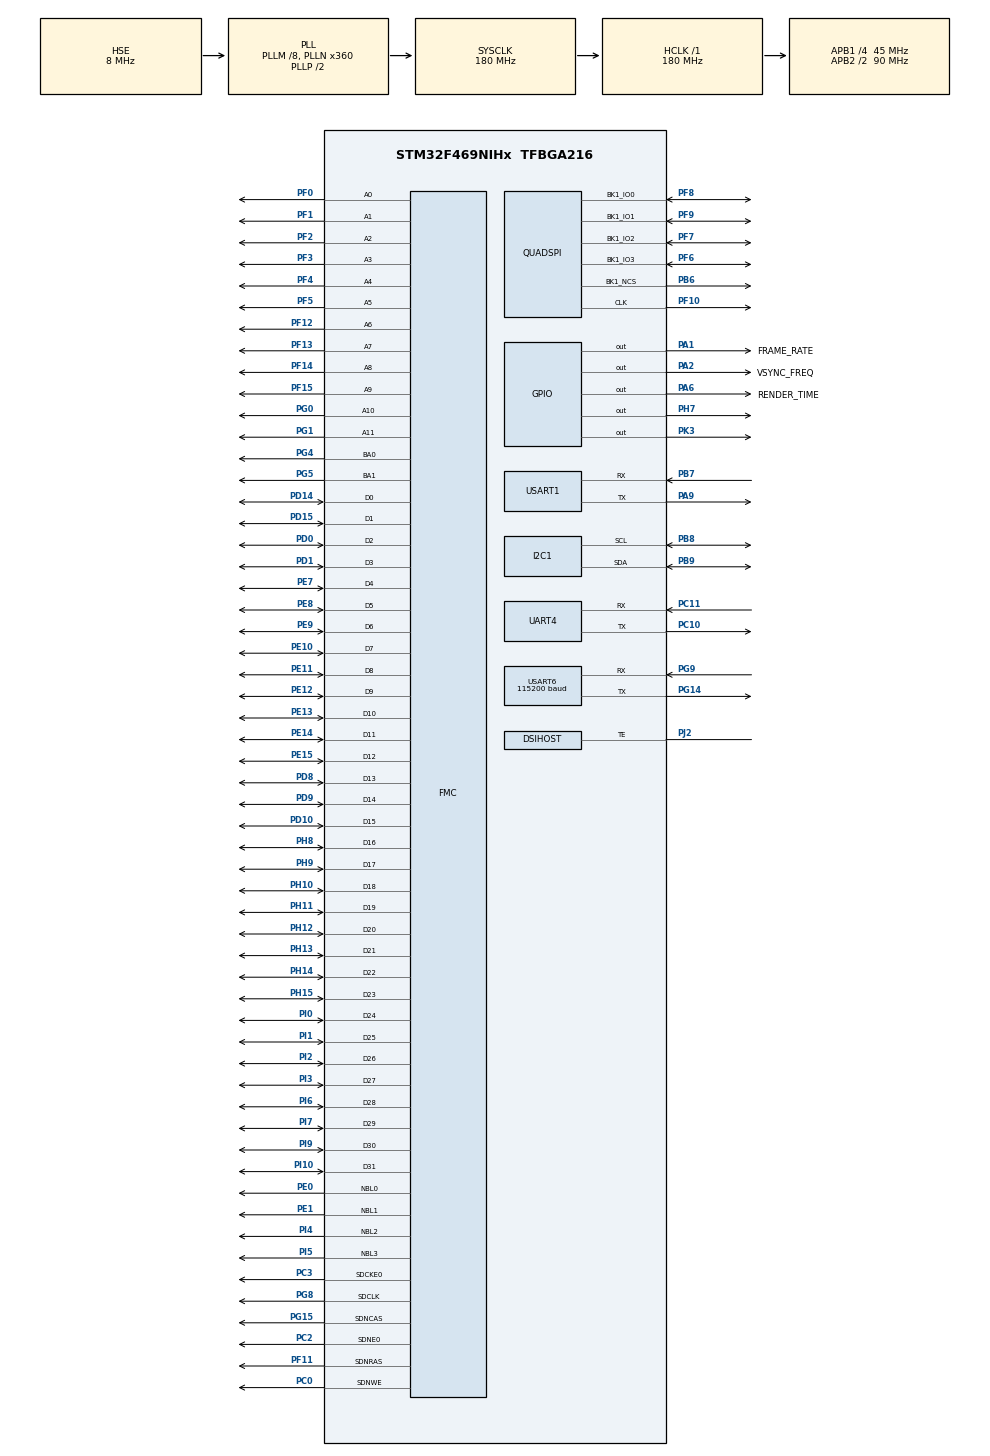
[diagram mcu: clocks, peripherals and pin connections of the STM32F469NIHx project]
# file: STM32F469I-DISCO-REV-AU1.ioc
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DMA2D.ColorMode=DMA2D_OUTPUT_ARGB8888
DSIHOST.AcknowledgeRequest=DSI_ACKNOWLEDGE_ENABLE
DSIHOST.AutomaticRefresh=DSI_AR_DISABLE
DSIHOST.CommandSize=200
DSIHOST.LPDcsLongWrite=DSI_LP_DLW_ENABLE
DSIHOST.LPDcsShortReadNoP=DSI_LP_DSR0P_ENABLE
DSIHOST.LPDcsShortWriteNoP=DSI_LP_DSW0P_ENABLE
DSIHOST.LPDcsShortWriteOneP=DSI_LP_DSW1P_ENABLE
DSIHOST.LPGenLongWrite=DSI_LP_GLW_ENABLE
DSIHOST.LPGenShortReadNoP=DSI_LP_GSR0P_ENABLE
DSIHOST.LPGenShortReadOneP=DSI_LP_GSR1P_ENABLE
DSIHOST.LPGenShortReadTwoP=DSI_LP_GSR2P_ENABLE
DSIHOST.LPGenShortWriteNoP=DSI_LP_GSW0P_ENABLE
DSIHOST.LPGenShortWriteOneP=DSI_LP_GSW1P_ENABLE
DSIHOST.LPGenShortWriteTwoP=DSI_LP_GSW2P_ENABLE
DSIHOST.LPMaxReadPacket=DSI_LP_MRDP_ENABLE
DSIHOST.NumberOfLanes=DSI_TWO_DATA_LANES
DSIHOST.TEAcknowledgeRequest=DSI_TE_ACKNOWLEDGE_ENABLE
DSIHOST.TimeoutCkdiv=1
DSIHOST_CKN.Mode=DSIHost_Adapted_TE
DSIHOST_CKN.Signal=DSIHOST_CKN
DSIHOST_CKP.Mode=DSIHost_Adapted_TE
DSIHOST_CKP.Signal=DSIHOST_CKP
DSIHOST_D0N.Mode=DSIHost_Adapted_TE
DSIHOST_D0N.Signal=DSIHOST_D0N
DSIHOST_D0P.Mode=DSIHost_Adapted_TE
DSIHOST_D0P.Signal=DSIHOST_D0P
DSIHOST_D1N.Mode=DSIHost_Adapted_TE
DSIHOST_D1N.Signal=DSIHOST_D1N
DSIHOST_D1P.Mode=DSIHost_Adapted_TE
DSIHOST_D1P.Signal=DSIHOST_D1P
Dma.Request0=UART4_RX
Dma.Request1=UART4_TX
Dma.UART4_RX.0.Direction=DMA_PERIPH_TO_MEMORY
Dma.UART4_RX.0.FIFOMode=DMA_FIFOMODE_DISABLE
Dma.UART4_RX.0.Instance=DMA1_Stream2
Dma.UART4_RX.0.MemDataAlignment=DMA_MDATAALIGN_BYTE
Dma.UART4_RX.0.MemInc=DMA_MINC_ENABLE
Dma.UART4_RX.0.Mode=DMA_NORMAL
Dma.UART4_RX.0.PeriphDataAlignment=DMA_PDATAALIGN_BYTE
Dma.UART4_RX.0.PeriphInc=DMA_PINC_DISABLE
Dma.UART4_RX.0.Priority=DMA_PRIORITY_LOW
Dma.UART4_TX.1.Direction=DMA_MEMORY_TO_PERIPH
Dma.UART4_TX.1.FIFOMode=DMA_FIFOMODE_DISABLE
Dma.UART4_TX.1.Instance=DMA1_Stream4
Dma.UART4_TX.1.MemDataAlignment=DMA_MDATAALIGN_BYTE
Dma.UART4_TX.1.MemInc=DMA_MINC_ENABLE
Dma.UART4_TX.1.Mode=DMA_NORMAL
Dma.UART4_TX.1.PeriphDataAlignment=DMA_PDATAALIGN_BYTE
Dma.UART4_TX.1.PeriphInc=DMA_PINC_DISABLE
Dma.UART4_TX.1.Priority=DMA_PRIORITY_LOW
FMC.CASLatency1=FMC_SDRAM_CAS_LATENCY_3
FMC.ExitSelfRefreshDelay1=7
FMC.LoadToActiveDelay1=2
FMC.RCDDelay1=2
FMC.RPDelay1=2
FMC.ReadBurst1=FMC_SDRAM_RBURST_ENABLE
FMC.ReadPipeDelay1=FMC_SDRAM_RPIPE_DELAY_2
FMC.RowCycleDelay1=7
FMC.SelfRefreshTime1=4
FMC.WriteRecoveryTime1=3
FREERTOS.Queues01=uartQueue,2,uint16_t,0,Dynamic,NULL,NULL
FREERTOS.Tasks01=defaultTask,24,128,StartDefaultTask,Default,NULL,Dynamic,NULL,NULL;TouchGFXTask,24,4096,TouchGFX_Task,As external,NULL,Dynamic,NULL,NULL
FREERTOS.configTOTAL_HEAP_SIZE=32768
FREERTOS.configUSE_APPLICATION_TASK_TAG=1
FREERTOS.configUSE_IDLE_HOOK=1
FREERTOS.configUSE_TRACE_FACILITY=1
I2C1.I2C_Mode=I2C_Fast
LTDC.ActiveW=200
LTDC.Alpha_L0=255
LTDC.FBStartAdress_L0=0xC0000000
LTDC.HBP=1
LTDC.HFP=1
LTDC.HSPolarity=LTDC_HSPOLARITY_AH
LTDC.HSync=2
LTDC.ImageHeight_L0=480
LTDC.ImageWidth_L0=200
LTDC.Layers=0
LTDC.PixelFormat_L0=LTDC_PIXEL_FORMAT_RGB565
LTDC.VBP=1
LTDC.VFP=1
LTDC.VSPolarity=LTDC_VSPOLARITY_AH
LTDC.VSync=2
LTDC.WindowX1_L0=200
LTDC.WindowY1_L0=480
Mcu.Family=STM32F4
Mcu.Name=STM32F469NIHx
Mcu.Package=TFBGA216
NVIC.DMA1_Stream2_IRQn=true\:5\:0\:false\:false\:true\:true\:false\:true\:true
NVIC.DMA1_Stream4_IRQn=true\:5\:0\:false\:false\:true\:true\:false\:true\:true
NVIC.DMA2D_IRQn=true\:5\:0\:true\:false\:true\:false\:true\:true\:true
NVIC.DSI_IRQn=true\:5\:0\:true\:false\:true\:false\:true\:true\:true
NVIC.LTDC_IRQn=true\:5\:0\:true\:false\:true\:false\:true\:true\:true
NVIC.PriorityGroup=NVIC_PRIORITYGROUP_4
NVIC.TIM6_DAC_IRQn=true\:0\:0\:false\:false\:true\:false\:false\:true\:true
NVIC.TimeBase=TIM6_DAC_IRQn
NVIC.TimeBaseIP=TIM6
NVIC.UART4_IRQn=true\:5\:0\:false\:false\:true\:true\:true\:true\:true
NVIC.USART1_IRQn=true\:5\:0\:false\:false\:true\:true\:true\:true\:true
NVIC.USART6_IRQn=true\:5\:0\:false\:false\:true\:true\:true\:true\:true
PA1.GPIO_Label=FRAME_RATE
PA1.GPIO_Speed=GPIO_SPEED_FREQ_VERY_HIGH
PA1.Signal=GPIO_Output
PA2.GPIO_Label=VSYNC_FREQ
PA2.GPIO_Speed=GPIO_SPEED_FREQ_VERY_HIGH
PA2.Signal=GPIO_Output
PA6.GPIO_Label=RENDER_TIME
PA6.GPIO_Speed=GPIO_SPEED_FREQ_VERY_HIGH
PA6.Signal=GPIO_Output
PA9.Mode=Asynchronous
PA9.Signal=USART1_TX
PB6.Mode=Single Bank 1
PB6.Signal=QUADSPI_BK1_NCS
PB7.Mode=Asynchronous
PB7.Signal=USART1_RX
PB8.GPIO_Pu=GPIO_PULLUP
PB8.Mode=I2C
PB8.Signal=I2C1_SCL
PB9.GPIO_Pu=GPIO_PULLUP
PB9.Mode=I2C
PB9.Signal=I2C1_SDA
PC0.Signal=FMC_SDNWE
PC10.Mode=Asynchronous
PC10.Signal=UART4_TX
PC11.Mode=Asynchronous
PC11.Signal=UART4_RX
PC2.Mode=SdramChipSelect1_1
PC2.Signal=FMC_SDNE0
PC3.Mode=SdramChipSelect1_1
PC3.Signal=FMC_SDCKE0
PD0.Signal=FMC_D2_DA2
PD1.Signal=FMC_D3_DA3
PD10.Signal=FMC_D15_DA15
PD14.Signal=FMC_D0_DA0
PD15.Signal=FMC_D1_DA1
PD8.Signal=FMC_D13_DA13
PD9.Signal=FMC_D14_DA14
PE0.Signal=FMC_NBL0
PE1.Signal=FMC_NBL1
PE10.Signal=FMC_D7_DA7
PE11.Signal=FMC_D8_DA8
PE12.Signal=FMC_D9_DA9
PE13.Signal=FMC_D10_DA10
PE14.Signal=FMC_D11_DA11
PE15.Signal=FMC_D12_DA12
PE7.Signal=FMC_D4_DA4
PE8.Signal=FMC_D5_DA5
PE9.Signal=FMC_D6_DA6
PF0.Signal=FMC_A0
PF1.Signal=FMC_A1
PF10.Mode=Single Bank 1
PF10.Signal=QUADSPI_CLK
PF11.Signal=FMC_SDNRAS
PF12.Signal=FMC_A6
PF13.Signal=FMC_A7
PF14.Signal=FMC_A8
PF15.Signal=FMC_A9
PF2.Signal=FMC_A2
PF3.Signal=FMC_A3
PF4.Signal=FMC_A4
PF5.Signal=FMC_A5
PF6.Mode=Single Bank 1
PF6.Signal=QUADSPI_BK1_IO3
PF7.Mode=Single Bank 1
PF7.Signal=QUADSPI_BK1_IO2
PF8.Mode=Single Bank 1
PF8.Signal=QUADSPI_BK1_IO0
PF9.Mode=Single Bank 1
PF9.Signal=QUADSPI_BK1_IO1
PG0.Signal=FMC_A10
PG1.Signal=FMC_A11
PG14.Mode=Asynchronous
PG14.Signal=USART6_TX
PG15.Signal=FMC_SDNCAS
PG4.Signal=FMC_A14_BA0
PG5.Signal=FMC_A15_BA1
PG8.Signal=FMC_SDCLK
PG9.Mode=Asynchronous
PG9.Signal=USART6_RX
PH0/OSC_IN.Mode=HSE-External-Oscillator
PH0/OSC_IN.Signal=RCC_OSC_IN
PH1/OSC_OUT.Mode=HSE-External-Oscillator
PH1/OSC_OUT.Signal=RCC_OSC_OUT
PH10.Signal=FMC_D18
PH11.Signal=FMC_D19
PH12.Signal=FMC_D20
PH13.Signal=FMC_D21
PH14.Signal=FMC_D22
PH15.Signal=FMC_D23
PH7.GPIO_ModeDefaultOutputPP=GPIO_MODE_OUTPUT_PP
PH7.GPIO_Speed=GPIO_SPEED_FREQ_VERY_HIGH
PH7.PinState=GPIO_PIN_RESET
PH7.Signal=GPIO_Output
PH8.Signal=FMC_D16
PH9.Signal=FMC_D17
PI0.Signal=FMC_D24
PI1.Signal=FMC_D25
PI10.Signal=FMC_D31
PI2.Signal=FMC_D26
PI3.Signal=FMC_D27
PI4.Signal=FMC_NBL2
PI5.Signal=FMC_NBL3
PI6.Signal=FMC_D28
PI7.Signal=FMC_D29
PI9.Signal=FMC_D30
PJ2.Mode=DSIHost_Adapted_TE
PJ2.Signal=DSIHOST_TE
PK3.GPIO_ModeDefaultOutputPP=GPIO_MODE_OUTPUT_OD
PK3.PinState=GPIO_PIN_SET
PK3.Signal=GPIO_Output
ProjectManager.HeapSize=0x1000
ProjectManager.StackSize=0x1000
ProjectManager.TargetToolchain=STM32CubeIDE
QUADSPI.ChipSelectHighTime=QSPI_CS_HIGH_TIME_5_CYCLE
QUADSPI.ClockPrescaler=1
QUADSPI.FlashSize=27
QUADSPI.SampleShifting=QSPI_SAMPLE_SHIFTING_HALFCYCLE
RCC.AHBFreq_Value=180000000
RCC.APB1CLKDivider=RCC_HCLK_DIV4
RCC.APB1Freq_Value=45000000
RCC.APB1TimFreq_Value=90000000
RCC.APB2CLKDivider=RCC_HCLK_DIV2
RCC.APB2Freq_Value=90000000
RCC.APB2TimFreq_Value=180000000
RCC.CortexFreq_Value=180000000
RCC.HCLKFreq_Value=180000000
RCC.HSE_VALUE=8000000
RCC.PLLDSIIDF=DSI_PLL_IN_DIV2
RCC.PLLDSINDIV=125
RCC.PLLM=8
RCC.PLLN=360
RCC.PLLR=6
RCC.PLLSAIN=360
RCC.PLLSAIR=6
RCC.PLLSourceVirtual=RCC_PLLSOURCE_HSE
RCC.SYSCLKFreq_VALUE=180000000
RCC.SYSCLKSource=RCC_SYSCLKSOURCE_PLLCLK
RCC.USBFreq_Value=90000000
RCC.VCOOutputFreq_Value=360000000
SH.FMC_A0.0=FMC_A0,12b-sda1
SH.FMC_A1.0=FMC_A1,12b-sda1
SH.FMC_A10.0=FMC_A10,12b-sda1
SH.FMC_A11.0=FMC_A11,12b-sda1
SH.FMC_A14_BA0.0=FMC_BA0,FourSdramBanks1
SH.FMC_A15_BA1.0=FMC_BA1,FourSdramBanks1
SH.FMC_A2.0=FMC_A2,12b-sda1
SH.FMC_A3.0=FMC_A3,12b-sda1
SH.FMC_A4.0=FMC_A4,12b-sda1
SH.FMC_A5.0=FMC_A5,12b-sda1
SH.FMC_A6.0=FMC_A6,12b-sda1
SH.FMC_A7.0=FMC_A7,12b-sda1
SH.FMC_A8.0=FMC_A8,12b-sda1
SH.FMC_A9.0=FMC_A9,12b-sda1
SH.FMC_D0_DA0.0=FMC_D0,sd-32b-d1
SH.FMC_D10_DA10.0=FMC_D10,sd-32b-d1
SH.FMC_D11_DA11.0=FMC_D11,sd-32b-d1
SH.FMC_D12_DA12.0=FMC_D12,sd-32b-d1
SH.FMC_D13_DA13.0=FMC_D13,sd-32b-d1
SH.FMC_D14_DA14.0=FMC_D14,sd-32b-d1
SH.FMC_D15_DA15.0=FMC_D15,sd-32b-d1
SH.FMC_D16.0=FMC_D16,sd-32b-d1
SH.FMC_D17.0=FMC_D17,sd-32b-d1
SH.FMC_D18.0=FMC_D18,sd-32b-d1
SH.FMC_D19.0=FMC_D19,sd-32b-d1
SH.FMC_D1_DA1.0=FMC_D1,sd-32b-d1
SH.FMC_D20.0=FMC_D20,sd-32b-d1
SH.FMC_D21.0=FMC_D21,sd-32b-d1
SH.FMC_D22.0=FMC_D22,sd-32b-d1
SH.FMC_D23.0=FMC_D23,sd-32b-d1
SH.FMC_D24.0=FMC_D24,sd-32b-d1
SH.FMC_D25.0=FMC_D25,sd-32b-d1
SH.FMC_D26.0=FMC_D26,sd-32b-d1
SH.FMC_D27.0=FMC_D27,sd-32b-d1
SH.FMC_D28.0=FMC_D28,sd-32b-d1
SH.FMC_D29.0=FMC_D29,sd-32b-d1
SH.FMC_D2_DA2.0=FMC_D2,sd-32b-d1
SH.FMC_D30.0=FMC_D30,sd-32b-d1
SH.FMC_D31.0=FMC_D31,sd-32b-d1
SH.FMC_D3_DA3.0=FMC_D3,sd-32b-d1
SH.FMC_D4_DA4.0=FMC_D4,sd-32b-d1
SH.FMC_D5_DA5.0=FMC_D5,sd-32b-d1
SH.FMC_D6_DA6.0=FMC_D6,sd-32b-d1
SH.FMC_D7_DA7.0=FMC_D7,sd-32b-d1
SH.FMC_D8_DA8.0=FMC_D8,sd-32b-d1
SH.FMC_D9_DA9.0=FMC_D9,sd-32b-d1
SH.FMC_NBL0.0=FMC_NBL0,Sd4ByteEnable1
SH.FMC_NBL1.0=FMC_NBL1,Sd4ByteEnable1
SH.FMC_NBL2.0=FMC_NBL2,Sd4ByteEnable1
SH.FMC_NBL3.0=FMC_NBL3,Sd4ByteEnable1
SH.FMC_SDCLK.0=FMC_SDCLK,12b-sda1
SH.FMC_SDNCAS.0=FMC_SDNCAS,12b-sda1
SH.FMC_SDNRAS.0=FMC_SDNRAS,12b-sda1
SH.FMC_SDNWE.0=FMC_SDNWE,12b-sda1
STMicroelectronics.X-CUBE-TOUCHGFX.4.23.1.ApplicationCcGraphicsJjApplication=TouchGFXOoGenerator
STMicroelectronics.X-CUBE-TOUCHGFX.4.23.1.tgfx_address1=0xC0000000
STMicroelectronics.X-CUBE-TOUCHGFX.4.23.1.tgfx_custom_height=480
STMicroelectronics.X-CUBE-TOUCHGFX.4.23.1.tgfx_custom_width=800
STMicroelectronics.X-CUBE-TOUCHGFX.4.23.1.tgfx_display_interface=disp_custom
STMicroelectronics.X-CUBE-TOUCHGFX.4.23.1.tgfx_hardware_accelerator=dma_2d
STMicroelectronics.X-CUBE-TOUCHGFX.4.23.1.tgfx_location=By Address
STMicroelectronics.X-CUBE-TOUCHGFX.4.23.1.tgfx_vector_fonts=Enabled
STMicroelectronics.X-CUBE-TOUCHGFX.4.23.1.tgfx_vector_rendering=Software
UART4.VirtualMode=Asynchronous
USART1.VirtualMode=VM_ASYNC
USART6.BaudRate=115200
USART6.VirtualMode=VM_ASYNC
VP_CRC_VS_CRC.Mode=CRC_Activate
VP_DMA2D_VS_DMA2D.Mode=DMA2D_Activate
VP_FREERTOS_VS_CMSIS_V2.Mode=CMSIS_V2
VP_LTDC_DSIMode.Mode=RGB565
VP_STMicroelectronics.X-CUBE-TOUCHGFX_VS_GraphicsJjApplication_4.23.1.Mode=GraphicsJjApplication
VP_SYS_VS_tim6.Mode=TIM6
board=custom

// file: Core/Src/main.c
/* USER CODE BEGIN Header */
/**
  ******************************************************************************
  * @file           : main.c
  * @brief          : Main program body
  ******************************************************************************
  * @attention
  *
  * <h2><center>&copy; Copyright (c) 2020 STMicroelectronics.
  * All rights reserved.</center></h2>
  *
  * This software component is licensed by ST under Ultimate Liberty license
  * SLA0044, the "License"; You may not use this file except in compliance with
  * the License. You may obtain a copy of the License at:
  *                             www.st.com/SLA0044
  *
  ******************************************************************************
  */
/* USER CODE END Header */
#include "main.h"
#include "cmsis_os.h"
#include "app_touchgfx.h"

/* USER CODE BEGIN Includes */
#include "../Components/nt35510/nt35510.h"
#include "stm32469i_discovery_sdram.h"
#include "stm32469i_discovery_qspi.h"
/* USER CODE END Includes */

/* USER CODE BEGIN PD */
/* DISPLAY */
#define LCD_ORIENTATION_LANDSCAPE 0x01
/* USER CODE END PD */

CRC_HandleTypeDef hcrc;

DMA2D_HandleTypeDef hdma2d;

DSI_HandleTypeDef hdsi;

I2C_HandleTypeDef hi2c1;

LTDC_HandleTypeDef hltdc;

QSPI_HandleTypeDef hqspi;

UART_HandleTypeDef huart4;
UART_HandleTypeDef huart1;
UART_HandleTypeDef huart6;
DMA_HandleTypeDef hdma_uart4_rx;
DMA_HandleTypeDef hdma_uart4_tx;

SDRAM_HandleTypeDef hsdram1;

/* Definitions for defaultTask */
osThreadId_t defaultTaskHandle;
const osThreadAttr_t defaultTask_attributes = {
  .name = "defaultTask",
  .stack_size = 128 * 4,
  .priority = (osPriority_t) osPriorityNormal,
};
/* Definitions for TouchGFXTask */
osThreadId_t TouchGFXTaskHandle;
const osThreadAttr_t TouchGFXTask_attributes = {
  .name = "TouchGFXTask",
  .stack_size = 4096 * 4,
  .priority = (osPriority_t) osPriorityNormal,
};
/* Definitions for uartQueue */
osMessageQueueId_t uartQueueHandle;
const osMessageQueueAttr_t uartQueue_attributes = {
  .name = "uartQueue"
};
/* USER CODE BEGIN PV */
uint8_t data [2048];
/* USER CODE END PV */

void SystemClock_Config(void);
static void MX_GPIO_Init(void);
static void MX_DMA_Init(void);
static void MX_CRC_Init(void);
static void MX_DMA2D_Init(void);
static void MX_DSIHOST_DSI_Init(void);
static void MX_FMC_Init(void);
static void MX_LTDC_Init(void);
static void MX_QUADSPI_Init(void);
static void MX_I2C1_Init(void);
static void MX_UART4_Init(void);
static void MX_USART6_UART_Init(void);
static void MX_USART1_UART_Init(void);
void StartDefaultTask(void *argument);
extern void TouchGFX_Task(void *argument);

/* USER CODE BEGIN 0 */

uint8_t RxData[2048];
uartData_t *uartData_q;

void HAL_UARTEx_RxEventCallback(UART_HandleTypeDef *huart, uint16_t Size)
{
	RxData[Size] = '\0';
 	if (osMessageQueueGetSpace(uartQueueHandle)>0)
	{
		strncpy((char*)data, (char *)RxData, Size+1);
		uartData_q->size = Size+1;
		osMessageQueuePut(uartQueueHandle, &data, 0, 0);
		memset(RxData,'\0',2048);
	}
	HAL_UARTEx_ReceiveToIdle_IT(&huart6, RxData, 2048);
}

/* USER CODE END 0 */

int main(void)
{

  /* MCU Configuration--------------------------------------------------------*/

  /* Reset of all peripherals, Initializes the Flash interface and the Systick. */
  HAL_Init();

  /* Configure the system clock */
  SystemClock_Config();

  /* Initialize all configured peripherals */
  MX_GPIO_Init();
  MX_DMA_Init();
  MX_CRC_Init();
  MX_DMA2D_Init();
  MX_DSIHOST_DSI_Init();
  MX_FMC_Init();
  MX_LTDC_Init();
  MX_QUADSPI_Init();
  MX_I2C1_Init();
  MX_UART4_Init();
  MX_USART6_UART_Init();
  MX_USART1_UART_Init();
  MX_TouchGFX_Init();
  /* Call PreOsInit function */
  MX_TouchGFX_PreOSInit();

  /* Init scheduler */
  osKernelInitialize();

  /* Create the queue(s) */
  /* creation of uartQueue */
  uartQueueHandle = osMessageQueueNew (2, sizeof(uartData_t), &uartQueue_attributes);

  /* Create the thread(s) */
  /* creation of defaultTask */
  defaultTaskHandle = osThreadNew(StartDefaultTask, NULL, &defaultTask_attributes);

  /* creation of TouchGFXTask */
  TouchGFXTaskHandle = osThreadNew(TouchGFX_Task, NULL, &TouchGFXTask_attributes);

  /* Start scheduler */
  osKernelStart();

  /* We should never get here as control is now taken by the scheduler */
  /* Infinite loop */
  while (1)
  {

  }
}

void SystemClock_Config(void)
{
  RCC_OscInitTypeDef RCC_OscInitStruct = {0};
  RCC_ClkInitTypeDef RCC_ClkInitStruct = {0};

  /** Configure the main internal regulator output voltage
  */
  __HAL_RCC_PWR_CLK_ENABLE();
  __HAL_PWR_VOLTAGESCALING_CONFIG(PWR_REGULATOR_VOLTAGE_SCALE1);

  /** Initializes the RCC Oscillators according to the specified parameters
  * in the RCC_OscInitTypeDef structure.
  */
  RCC_OscInitStruct.OscillatorType = RCC_OSCILLATORTYPE_HSE;
  RCC_OscInitStruct.HSEState = RCC_HSE_ON;
  RCC_OscInitStruct.PLL.PLLState = RCC_PLL_ON;
  RCC_OscInitStruct.PLL.PLLSource = RCC_PLLSOURCE_HSE;
  RCC_OscInitStruct.PLL.PLLM = 8;
  RCC_OscInitStruct.PLL.PLLN = 360;
  RCC_OscInitStruct.PLL.PLLP = RCC_PLLP_DIV2;
  RCC_OscInitStruct.PLL.PLLQ = 4;
  RCC_OscInitStruct.PLL.PLLR = 6;
  if (HAL_RCC_OscConfig(&RCC_OscInitStruct) != HAL_OK)
  {
    Error_Handler();
  }

  /** Activate the Over-Drive mode
  */
  if (HAL_PWREx_EnableOverDrive() != HAL_OK)
  {
    Error_Handler();
  }

  /** Initializes the CPU, AHB and APB buses clocks
  */
  RCC_ClkInitStruct.ClockType = RCC_CLOCKTYPE_HCLK|RCC_CLOCKTYPE_SYSCLK
                              |RCC_CLOCKTYPE_PCLK1|RCC_CLOCKTYPE_PCLK2;
  RCC_ClkInitStruct.SYSCLKSource = RCC_SYSCLKSOURCE_PLLCLK;
  RCC_ClkInitStruct.AHBCLKDivider = RCC_SYSCLK_DIV1;
  RCC_ClkInitStruct.APB1CLKDivider = RCC_HCLK_DIV4;
  RCC_ClkInitStruct.APB2CLKDivider = RCC_HCLK_DIV2;

  if (HAL_RCC_ClockConfig(&RCC_ClkInitStruct, FLASH_LATENCY_5) != HAL_OK)
  {
    Error_Handler();
  }
}

static void MX_CRC_Init(void)
{

  hcrc.Instance = CRC;
  if (HAL_CRC_Init(&hcrc) != HAL_OK)
  {
    Error_Handler();
  }

}

static void MX_DMA2D_Init(void)
{

  hdma2d.Instance = DMA2D;
  hdma2d.Init.Mode = DMA2D_M2M;
  hdma2d.Init.ColorMode = DMA2D_OUTPUT_ARGB8888;
  hdma2d.Init.OutputOffset = 0;
  hdma2d.LayerCfg[1].InputOffset = 0;
  hdma2d.LayerCfg[1].InputColorMode = DMA2D_INPUT_ARGB8888;
  hdma2d.LayerCfg[1].AlphaMode = DMA2D_NO_MODIF_ALPHA;
  hdma2d.LayerCfg[1].InputAlpha = 0;
  if (HAL_DMA2D_Init(&hdma2d) != HAL_OK)
  {
    Error_Handler();
  }
  if (HAL_DMA2D_ConfigLayer(&hdma2d, 1) != HAL_OK)
  {
    Error_Handler();
  }

}

static void MX_DSIHOST_DSI_Init(void)
{

  /* USER CODE BEGIN DSIHOST_Init 0 */
  /* Activate XRES active low */
  HAL_GPIO_WritePin(GPIOH, GPIO_PIN_7, GPIO_PIN_RESET);

  HAL_Delay(20); /* wait 20 ms */

  /* Desactivate XRES */
  HAL_GPIO_WritePin(GPIOH, GPIO_PIN_7, GPIO_PIN_SET);

  /* Wait for 10ms after releasing XRES before sending commands */
  HAL_Delay(10);
  /* USER CODE END DSIHOST_Init 0 */

  DSI_PLLInitTypeDef PLLInit = {0};
  DSI_HOST_TimeoutTypeDef HostTimeouts = {0};
  DSI_PHY_TimerTypeDef PhyTimings = {0};
  DSI_LPCmdTypeDef LPCmd = {0};
  DSI_CmdCfgTypeDef CmdCfg = {0};

  hdsi.Instance = DSI;
  hdsi.Init.AutomaticClockLaneControl = DSI_AUTO_CLK_LANE_CTRL_DISABLE;
  hdsi.Init.TXEscapeCkdiv = 4;
  hdsi.Init.NumberOfLanes = DSI_TWO_DATA_LANES;
  PLLInit.PLLNDIV = 125;
  PLLInit.PLLIDF = DSI_PLL_IN_DIV2;
  PLLInit.PLLODF = DSI_PLL_OUT_DIV1;
  if (HAL_DSI_Init(&hdsi, &PLLInit) != HAL_OK)
  {
    Error_Handler();
  }
  HostTimeouts.TimeoutCkdiv = 1;
  HostTimeouts.HighSpeedTransmissionTimeout = 0;
  HostTimeouts.LowPowerReceptionTimeout = 0;
  HostTimeouts.HighSpeedReadTimeout = 0;
  HostTimeouts.LowPowerReadTimeout = 0;
  HostTimeouts.HighSpeedWriteTimeout = 0;
  HostTimeouts.HighSpeedWritePrespMode = DSI_HS_PM_DISABLE;
  HostTimeouts.LowPowerWriteTimeout = 0;
  HostTimeouts.BTATimeout = 0;
  if (HAL_DSI_ConfigHostTimeouts(&hdsi, &HostTimeouts) != HAL_OK)
  {
    Error_Handler();
  }
  PhyTimings.ClockLaneHS2LPTime = 28;
  PhyTimings.ClockLaneLP2HSTime = 33;
  PhyTimings.DataLaneHS2LPTime = 15;
  PhyTimings.DataLaneLP2HSTime = 25;
  PhyTimings.DataLaneMaxReadTime = 0;
  PhyTimings.StopWaitTime = 0;
  if (HAL_DSI_ConfigPhyTimer(&hdsi, &PhyTimings) != HAL_OK)
  {
    Error_Handler();
  }
  if (HAL_DSI_ConfigFlowControl(&hdsi, DSI_FLOW_CONTROL_BTA) != HAL_OK)
  {
    Error_Handler();
  }
  if (HAL_DSI_SetLowPowerRXFilter(&hdsi, 10000) != HAL_OK)
  {
    Error_Handler();
  }
  if (HAL_DSI_ConfigErrorMonitor(&hdsi, HAL_DSI_ERROR_NONE) != HAL_OK)
  {
    Error_Handler();
  }
  LPCmd.LPGenShortWriteNoP = DSI_LP_GSW0P_ENABLE;
  LPCmd.LPGenShortWriteOneP = DSI_LP_GSW1P_ENABLE;
  LPCmd.LPGenShortWriteTwoP = DSI_LP_GSW2P_ENABLE;
  LPCmd.LPGenShortReadNoP = DSI_LP_GSR0P_ENABLE;
  LPCmd.LPGenShortReadOneP = DSI_LP_GSR1P_ENABLE;
  LPCmd.LPGenShortReadTwoP = DSI_LP_GSR2P_ENABLE;
  LPCmd.LPGenLongWrite = DSI_LP_GLW_ENABLE;
  LPCmd.LPDcsShortWriteNoP = DSI_LP_DSW0P_ENABLE;
  LPCmd.LPDcsShortWriteOneP = DSI_LP_DSW1P_ENABLE;
  LPCmd.LPDcsShortReadNoP = DSI_LP_DSR0P_ENABLE;
  LPCmd.LPDcsLongWrite = DSI_LP_DLW_ENABLE;
  LPCmd.LPMaxReadPacket = DSI_LP_MRDP_ENABLE;
  LPCmd.AcknowledgeRequest = DSI_ACKNOWLEDGE_ENABLE;
  if (HAL_DSI_ConfigCommand(&hdsi, &LPCmd) != HAL_OK)
  {
    Error_Handler();
  }
  CmdCfg.VirtualChannelID = 0;
  CmdCfg.ColorCoding = DSI_RGB565;
  CmdCfg.CommandSize = 200;
  CmdCfg.TearingEffectSource = DSI_TE_EXTERNAL;
  CmdCfg.TearingEffectPolarity = DSI_TE_RISING_EDGE;
  CmdCfg.HSPolarity = DSI_HSYNC_ACTIVE_HIGH;
  CmdCfg.VSPolarity = DSI_VSYNC_ACTIVE_HIGH;
  CmdCfg.DEPolarity = DSI_DATA_ENABLE_ACTIVE_HIGH;
  CmdCfg.VSyncPol = DSI_VSYNC_RISING;
  CmdCfg.AutomaticRefresh = DSI_AR_DISABLE;
  CmdCfg.TEAcknowledgeRequest = DSI_TE_ACKNOWLEDGE_ENABLE;
  if (HAL_DSI_ConfigAdaptedCommandMode(&hdsi, &CmdCfg) != HAL_OK)
  {
    Error_Handler();
  }
  if (HAL_DSI_SetGenericVCID(&hdsi, 0) != HAL_OK)
  {
    Error_Handler();
  }

}

static void MX_I2C1_Init(void)
{

  hi2c1.Instance = I2C1;
  hi2c1.Init.ClockSpeed = 400000;
  hi2c1.Init.DutyCycle = I2C_DUTYCYCLE_2;
  hi2c1.Init.OwnAddress1 = 0;
  hi2c1.Init.AddressingMode = I2C_ADDRESSINGMODE_7BIT;
  hi2c1.Init.DualAddressMode = I2C_DUALADDRESS_DISABLE;
  hi2c1.Init.OwnAddress2 = 0;
  hi2c1.Init.GeneralCallMode = I2C_GENERALCALL_DISABLE;
  hi2c1.Init.NoStretchMode = I2C_NOSTRETCH_DISABLE;
  if (HAL_I2C_Init(&hi2c1) != HAL_OK)
  {
    Error_Handler();
  }
  /* USER CODE BEGIN I2C1_Init 2 */
  HAL_I2C_DeInit(&hi2c1);
  /* USER CODE END I2C1_Init 2 */

}

static void MX_LTDC_Init(void)
{

  LTDC_LayerCfgTypeDef pLayerCfg = {0};

  hltdc.Instance = LTDC;
  hltdc.Init.HSPolarity = LTDC_HSPOLARITY_AH;
  hltdc.Init.VSPolarity = LTDC_VSPOLARITY_AH;
  hltdc.Init.DEPolarity = LTDC_DEPOLARITY_AL;
  hltdc.Init.PCPolarity = LTDC_PCPOLARITY_IPC;
  hltdc.Init.HorizontalSync = 1;
  hltdc.Init.VerticalSync = 1;
  hltdc.Init.AccumulatedHBP = 2;
  hltdc.Init.AccumulatedVBP = 2;
  hltdc.Init.AccumulatedActiveW = 202;
  hltdc.Init.AccumulatedActiveH = 482;
  hltdc.Init.TotalWidth = 203;
  hltdc.Init.TotalHeigh = 483;
  hltdc.Init.Backcolor.Blue = 0;
  hltdc.Init.Backcolor.Green = 0;
  hltdc.Init.Backcolor.Red = 0;
  if (HAL_LTDC_Init(&hltdc) != HAL_OK)
  {
    Error_Handler();
  }
  pLayerCfg.WindowX0 = 0;
  pLayerCfg.WindowX1 = 200;
  pLayerCfg.WindowY0 = 0;
  pLayerCfg.WindowY1 = 480;
  pLayerCfg.PixelFormat = LTDC_PIXEL_FORMAT_RGB565;
  pLayerCfg.Alpha = 255;
  pLayerCfg.Alpha0 = 0;
  pLayerCfg.BlendingFactor1 = LTDC_BLENDING_FACTOR1_CA;
  pLayerCfg.BlendingFactor2 = LTDC_BLENDING_FACTOR2_CA;
  pLayerCfg.FBStartAdress = 0xC0000000;
  pLayerCfg.ImageWidth = 200;
  pLayerCfg.ImageHeight = 480;
  pLayerCfg.Backcolor.Blue = 0;
  pLayerCfg.Backcolor.Green = 0;
  pLayerCfg.Backcolor.Red = 0;
  if (HAL_LTDC_ConfigLayer(&hltdc, &pLayerCfg, 0) != HAL_OK)
  {
    Error_Handler();
  }
  /* USER CODE BEGIN LTDC_Init 2 */
  __HAL_LTDC_DISABLE(&hltdc);
  DSI_LPCmdTypeDef LPCmd;

  HAL_DSI_Start(&hdsi);
  NT35510_Init(NT35510_FORMAT_RBG565, LCD_ORIENTATION_LANDSCAPE);
  HAL_DSI_ShortWrite(&hdsi, 0, DSI_DCS_SHORT_PKT_WRITE_P1, NT35510_CMD_DISPOFF, 0x00);

  LPCmd.LPGenShortWriteNoP = DSI_LP_GSW0P_DISABLE;
  LPCmd.LPGenShortWriteOneP = DSI_LP_GSW1P_DISABLE;
  LPCmd.LPGenShortWriteTwoP = DSI_LP_GSW2P_DISABLE;
  LPCmd.LPGenShortReadNoP = DSI_LP_GSR0P_DISABLE;
  LPCmd.LPGenShortReadOneP = DSI_LP_GSR1P_DISABLE;
  LPCmd.LPGenShortReadTwoP = DSI_LP_GSR2P_DISABLE;
  LPCmd.LPGenLongWrite = DSI_LP_GLW_DISABLE;
  LPCmd.LPDcsShortWriteNoP = DSI_LP_DSW0P_DISABLE;
  LPCmd.LPDcsShortWriteOneP = DSI_LP_DSW1P_DISABLE;
  LPCmd.LPDcsShortReadNoP = DSI_LP_DSR0P_DISABLE;
  LPCmd.LPDcsLongWrite = DSI_LP_DLW_DISABLE;
  HAL_DSI_ConfigCommand(&hdsi, &LPCmd);

  HAL_LTDC_SetPitch(&hltdc, 800, 0);
  __HAL_LTDC_ENABLE(&hltdc);
  /* USER CODE END LTDC_Init 2 */

}

static void MX_QUADSPI_Init(void)
{

  /* QUADSPI parameter configuration*/
  hqspi.Instance = QUADSPI;
  hqspi.Init.ClockPrescaler = 1;
  hqspi.Init.FifoThreshold = 1;
  hqspi.Init.SampleShifting = QSPI_SAMPLE_SHIFTING_HALFCYCLE;
  hqspi.Init.FlashSize = 27;
  hqspi.Init.ChipSelectHighTime = QSPI_CS_HIGH_TIME_5_CYCLE;
  hqspi.Init.ClockMode = QSPI_CLOCK_MODE_0;
  hqspi.Init.FlashID = QSPI_FLASH_ID_1;
  hqspi.Init.DualFlash = QSPI_DUALFLASH_DISABLE;
  if (HAL_QSPI_Init(&hqspi) != HAL_OK)
  {
    Error_Handler();
  }
  /* USER CODE BEGIN QUADSPI_Init 2 */
  BSP_QSPI_DeInit();
  if(BSP_QSPI_Init() != QSPI_OK)
  {
    Error_Handler();
  }
  if(BSP_QSPI_EnableMemoryMappedMode() != QSPI_OK)
  {
    Error_Handler();
  }
  /* USER CODE END QUADSPI_Init 2 */

}

static void MX_UART4_Init(void)
{

  huart4.Instance = UART4;
  huart4.Init.BaudRate = 115200;
  huart4.Init.WordLength = UART_WORDLENGTH_8B;
  huart4.Init.StopBits = UART_STOPBITS_1;
  huart4.Init.Parity = UART_PARITY_NONE;
  huart4.Init.Mode = UART_MODE_TX_RX;
  huart4.Init.HwFlowCtl = UART_HWCONTROL_NONE;
  huart4.Init.OverSampling = UART_OVERSAMPLING_16;
  if (HAL_UART_Init(&huart4) != HAL_OK)
  {
    Error_Handler();
  }

}

static void MX_USART1_UART_Init(void)
{

  huart1.Instance = USART1;
  huart1.Init.BaudRate = 115200;
  huart1.Init.WordLength = UART_WORDLENGTH_8B;
  huart1.Init.StopBits = UART_STOPBITS_1;
  huart1.Init.Parity = UART_PARITY_NONE;
  huart1.Init.Mode = UART_MODE_TX_RX;
  huart1.Init.HwFlowCtl = UART_HWCONTROL_NONE;
  huart1.Init.OverSampling = UART_OVERSAMPLING_16;
  if (HAL_UART_Init(&huart1) != HAL_OK)
  {
    Error_Handler();
  }

}

static void MX_USART6_UART_Init(void)
{

  huart6.Instance = USART6;
  huart6.Init.BaudRate = 115200;
  huart6.Init.WordLength = UART_WORDLENGTH_8B;
  huart6.Init.StopBits = UART_STOPBITS_1;
  huart6.Init.Parity = UART_PARITY_NONE;
  huart6.Init.Mode = UART_MODE_TX_RX;
  huart6.Init.HwFlowCtl = UART_HWCONTROL_NONE;
  huart6.Init.OverSampling = UART_OVERSAMPLING_16;
  if (HAL_UART_Init(&huart6) != HAL_OK)
  {
    Error_Handler();
  }

}

static void MX_DMA_Init(void)
{

  /* DMA controller clock enable */
  __HAL_RCC_DMA1_CLK_ENABLE();

  /* DMA interrupt init */
  /* DMA1_Stream2_IRQn interrupt configuration */
  HAL_NVIC_SetPriority(DMA1_Stream2_IRQn, 5, 0);
  HAL_NVIC_EnableIRQ(DMA1_Stream2_IRQn);
  /* DMA1_Stream4_IRQn interrupt configuration */
  HAL_NVIC_SetPriority(DMA1_Stream4_IRQn, 5, 0);
  HAL_NVIC_EnableIRQ(DMA1_Stream4_IRQn);

}

/* FMC initialization function */
static void MX_FMC_Init(void)
{

  FMC_SDRAM_TimingTypeDef SdramTiming = {0};

  /** Perform the SDRAM1 memory initialization sequence
  */
  hsdram1.Instance = FMC_SDRAM_DEVICE;
  /* hsdram1.Init */
  hsdram1.Init.SDBank = FMC_SDRAM_BANK1;
  hsdram1.Init.ColumnBitsNumber = FMC_SDRAM_COLUMN_BITS_NUM_8;
  hsdram1.Init.RowBitsNumber = FMC_SDRAM_ROW_BITS_NUM_12;
  hsdram1.Init.MemoryDataWidth = FMC_SDRAM_MEM_BUS_WIDTH_32;
  hsdram1.Init.InternalBankNumber = FMC_SDRAM_INTERN_BANKS_NUM_4;
  hsdram1.Init.CASLatency = FMC_SDRAM_CAS_LATENCY_3;
  hsdram1.Init.WriteProtection = FMC_SDRAM_WRITE_PROTECTION_DISABLE;
  hsdram1.Init.SDClockPeriod = FMC_SDRAM_CLOCK_DISABLE;
  hsdram1.Init.ReadBurst = FMC_SDRAM_RBURST_ENABLE;
  hsdram1.Init.ReadPipeDelay = FMC_SDRAM_RPIPE_DELAY_2;
  /* SdramTiming */
  SdramTiming.LoadToActiveDelay = 2;
  SdramTiming.ExitSelfRefreshDelay = 7;
  SdramTiming.SelfRefreshTime = 4;
  SdramTiming.RowCycleDelay = 7;
  SdramTiming.WriteRecoveryTime = 3;
  SdramTiming.RPDelay = 2;
  SdramTiming.RCDDelay = 2;

  if (HAL_SDRAM_Init(&hsdram1, &SdramTiming) != HAL_OK)
  {
    Error_Handler( );
  }

  /* USER CODE BEGIN FMC_Init 2 */
  BSP_SDRAM_DeInit();
  if(BSP_SDRAM_Init() != SDRAM_OK)
  {
    Error_Handler();
  }
  /* USER CODE END FMC_Init 2 */
}

static void MX_GPIO_Init(void)
{
  GPIO_InitTypeDef GPIO_InitStruct = {0};

  /* GPIO Ports Clock Enable */
  __HAL_RCC_GPIOG_CLK_ENABLE();
  __HAL_RCC_GPIOE_CLK_ENABLE();
  __HAL_RCC_GPIOB_CLK_ENABLE();
  __HAL_RCC_GPIOD_CLK_ENABLE();
  __HAL_RCC_GPIOC_CLK_ENABLE();
  __HAL_RCC_GPIOI_CLK_ENABLE();
  __HAL_RCC_GPIOF_CLK_ENABLE();
  __HAL_RCC_GPIOK_CLK_ENABLE();
  __HAL_RCC_GPIOH_CLK_ENABLE();
  __HAL_RCC_GPIOA_CLK_ENABLE();
  __HAL_RCC_GPIOJ_CLK_ENABLE();

  /*Configure GPIO pin Output Level */
  HAL_GPIO_WritePin(GPIOK, GPIO_PIN_3, GPIO_PIN_SET);

  /*Configure GPIO pin Output Level */
  HAL_GPIO_WritePin(GPIOA, FRAME_RATE_Pin|VSYNC_FREQ_Pin|RENDER_TIME_Pin, GPIO_PIN_RESET);

  /*Configure GPIO pin Output Level */
  HAL_GPIO_WritePin(GPIOH, GPIO_PIN_7, GPIO_PIN_RESET);

  /*Configure GPIO pin : PK3 */
  GPIO_InitStruct.Pin = GPIO_PIN_3;
  GPIO_InitStruct.Mode = GPIO_MODE_OUTPUT_OD;
  GPIO_InitStruct.Pull = GPIO_NOPULL;
  GPIO_InitStruct.Speed = GPIO_SPEED_FREQ_LOW;
  HAL_GPIO_Init(GPIOK, &GPIO_InitStruct);

  /*Configure GPIO pins : FRAME_RATE_Pin VSYNC_FREQ_Pin RENDER_TIME_Pin */
  GPIO_InitStruct.Pin = FRAME_RATE_Pin|VSYNC_FREQ_Pin|RENDER_TIME_Pin;
  GPIO_InitStruct.Mode = GPIO_MODE_OUTPUT_PP;
  GPIO_InitStruct.Pull = GPIO_NOPULL;
  GPIO_InitStruct.Speed = GPIO_SPEED_FREQ_VERY_HIGH;
  HAL_GPIO_Init(GPIOA, &GPIO_InitStruct);

  /*Configure GPIO pin : PH7 */
  GPIO_InitStruct.Pin = GPIO_PIN_7;
  GPIO_InitStruct.Mode = GPIO_MODE_OUTPUT_PP;
  GPIO_InitStruct.Pull = GPIO_NOPULL;
  GPIO_InitStruct.Speed = GPIO_SPEED_FREQ_VERY_HIGH;
  HAL_GPIO_Init(GPIOH, &GPIO_InitStruct);

}

void StartDefaultTask(void *argument)
{
  /* USER CODE BEGIN 5 */
  /* Infinite loop */
    HAL_UARTEx_ReceiveToIdle_IT(&huart6, RxData, 2048);

	/*  HAL_UARTEx_ReceiveToIdle_DMA(&huart6, RxData, 50);
	  __HAL_DMA_DISABLE_IT(&hdma_usart6_rx,DMA_IT_HT);*/

  for(;;)
  {
//		HAL_UART_Transmit(&huart6,(const uint8_t *)"MUSTAFA",strlen("MUSTAFA"),HAL_MAX_DELAY);

    osDelay(100);
  }
  /* USER CODE END 5 */
}

void HAL_TIM_PeriodElapsedCallback(TIM_HandleTypeDef *htim)
{
  if (htim->Instance == TIM6) {
    HAL_IncTick();
  }
}

void Error_Handler(void)
{
}
